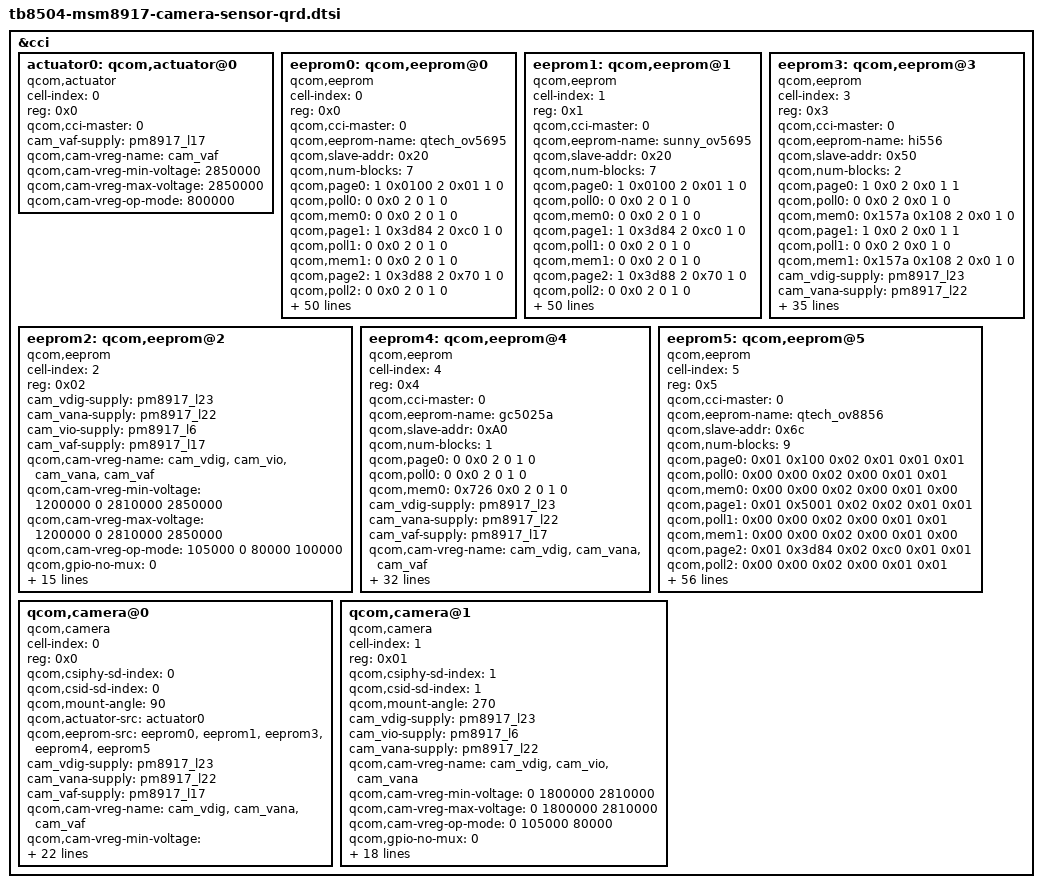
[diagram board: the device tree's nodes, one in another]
/*
 * Copyright (c) 2016, The Linux Foundation. All rights reserved.
 *
 * This program is free software; you can redistribute it and/or modify
 * it under the terms of the GNU General Public License version 2 and
 * only version 2 as published by the Free Software Foundation.
 *
 * This program is distributed in the hope that it will be useful,
 * but WITHOUT ANY WARRANTY; without even the implied warranty of
 * MERCHANTABILITY or FITNESS FOR A PARTICULAR PURPOSE.  See the
 * GNU General Public License for more details.
 */
&cci {
	actuator0: qcom,actuator@0 {
		cell-index = <0>;
		reg = <0x0>;
		compatible = "qcom,actuator";
		qcom,cci-master = <0>;
		cam_vaf-supply = <&pm8917_l17>;
		qcom,cam-vreg-name = "cam_vaf";
		qcom,cam-vreg-min-voltage = <2850000>;
		qcom,cam-vreg-max-voltage = <2850000>;
		qcom,cam-vreg-op-mode = <800000>;
	};

	eeprom0: qcom,eeprom@0 {
		cell-index = <0>;
		reg = <0x0>;
		compatible = "qcom,eeprom";
		qcom,cci-master = <0>;

		qcom,eeprom-name = "qtech_ov5695";
		qcom,slave-addr = <0x20>;
		qcom,num-blocks = <7>;
		qcom,page0 = <1 0x0100 2 0x01 1 0>;//Stream on mode
		qcom,poll0 = <0 0x0 2 0 1 0>;
		qcom,mem0 = <0 0x0 2 0 1 0>;
		qcom,page1 = <1 0x3d84 2 0xc0 1 0>;//manual made
		qcom,poll1 = <0 0x0 2 0 1 0>;
		qcom,mem1 = <0 0x0 2 0 1 0>;
		qcom,page2 = <1 0x3d88 2 0x70 1 0>;//star address high
		qcom,poll2 = <0 0x0 2 0 1 0>;
		qcom,mem2 = <0 0x0 2 0 1 0>;
		qcom,page3 = <1 0x3d89 2 0x0c 1 0>;//star address low
		qcom,poll3 = <0 0x0 2 0 1 0>;
		qcom,mem3 = <0 0x0 2 0 1 0>;
		qcom,page4 = <1 0x3d8a 2 0x70 1 0>;//end address high
		qcom,poll4 = <0 0x0 2 0 1 0>;
		qcom,mem4 = <0 0x0 2 0 1 0>;
		qcom,page5 = <1 0x3d8b 2 0x1b 1 0>;//end address low
		qcom,poll5 = <0 0x0 2 0 1 0>;
		qcom,mem5 = <0 0x0 2 0 1 0>;
		qcom,page6 = <1 0x3d81 2 0x01 1 5>;//Page Read Enable
		qcom,poll6 = <0 0x0 2 0 1 0>;
		qcom,mem6 = <16 0x700c 2 0 1 0>;//read 

		cam_vdig-supply = <&pm8917_l23>;
		cam_vana-supply = <&pm8917_l22>;
		cam_vaf-supply = <&pm8917_l17>;
		qcom,cam-vreg-name = "cam_vdig", "cam_vana", "cam_vaf";
		qcom,cam-vreg-min-voltage = <1200000 2810000 2850000>;
		qcom,cam-vreg-max-voltage = <1200000 2810000 2850000>;
		qcom,cam-vreg-op-mode = <100000 800000 800000>;
		pinctrl-names = "cam_default", "cam_suspend";
		pinctrl-0 = <&cam_sensor_mclk0_default
				&cam_sensor_rear_default>;
		pinctrl-1 = <&cam_sensor_mclk0_sleep
				&cam_sensor_rear_sleep>;
		gpios = <&tlmm 26 0>,
			<&tlmm 36 0>,
			<&tlmm 35 0>,
			<&tlmm 34 0>;
		qcom,gpio-reset = <1>;
		qcom,gpio-standby = <2>;
		qcom,gpio-vio = <3>;
		qcom,gpio-req-tbl-num = <0 1 2 3>;
		qcom,gpio-req-tbl-flags = <1 0 0 0>;
		qcom,gpio-req-tbl-label = "CAMIF_MCLK0",
					  "CAM_RESET0",
					  "CAM_STANDBY0",
					  "CAM_VIO0";

		qcom,cam-power-seq-type = "sensor_vreg",
					  "sensor_gpio",
					  "sensor_vreg",
					  "sensor_vreg",
					  "sensor_clk",
					  "sensor_gpio",
					  "sensor_gpio",
					  "sensor_gpio",
					  "sensor_gpio";
		qcom,cam-power-seq-val =  "cam_vaf",
					  "sensor_gpio_vio",
					  "cam_vana",
					  "cam_vdig",
					  "sensor_cam_mclk",
					  "sensor_gpio_standby",
					  "sensor_gpio_reset",
					  "sensor_gpio_standby",
					  "sensor_gpio_reset";
		qcom,cam-power-seq-cfg-val = <1 1 1 1 24000000 0 0 1 1>;
		qcom,cam-power-seq-delay = <5 0 0 0 1 1 1 1 1>;

		status = "ok";

		clocks = <&clock_gcc clk_mclk0_clk_src>,
				<&clock_gcc clk_gcc_camss_mclk0_clk>;
		clock-names = "cam_src_clk", "cam_clk";
		qcom,clock-rates = <19200000 0>;
		/delete-property/ cam_vio-supply;
	};
	eeprom1: qcom,eeprom@1 {
		cell-index = <1>;
		reg = <0x1>;
		compatible = "qcom,eeprom";
		qcom,cci-master = <0>;

		qcom,eeprom-name = "sunny_ov5695";
		qcom,slave-addr = <0x20>;
		qcom,num-blocks = <7>;
		qcom,page0 = <1 0x0100 2 0x01 1 0>;//Stream on mode
		qcom,poll0 = <0 0x0 2 0 1 0>;
		qcom,mem0 = <0 0x0 2 0 1 0>;
		qcom,page1 = <1 0x3d84 2 0xc0 1 0>;//manual made
		qcom,poll1 = <0 0x0 2 0 1 0>;
		qcom,mem1 = <0 0x0 2 0 1 0>;
		qcom,page2 = <1 0x3d88 2 0x70 1 0>;//star address high
		qcom,poll2 = <0 0x0 2 0 1 0>;
		qcom,mem2 = <0 0x0 2 0 1 0>;
		qcom,page3 = <1 0x3d89 2 0x0c 1 0>;//star address low
		qcom,poll3 = <0 0x0 2 0 1 0>;
		qcom,mem3 = <0 0x0 2 0 1 0>;
		qcom,page4 = <1 0x3d8a 2 0x70 1 0>;//end address high
		qcom,poll4 = <0 0x0 2 0 1 0>;
		qcom,mem4 = <0 0x0 2 0 1 0>;
		qcom,page5 = <1 0x3d8b 2 0x1b 1 0>;//end address low
		qcom,poll5 = <0 0x0 2 0 1 0>;
		qcom,mem5 = <0 0x0 2 0 1 0>;
		qcom,page6 = <1 0x3d81 2 0x01 1 5>;//Page Read Enable
		qcom,poll6 = <0 0x0 2 0 1 0>;
		qcom,mem6 = <16 0x700c 2 0 1 0>;//read 

		cam_vdig-supply = <&pm8917_l23>;
		cam_vana-supply = <&pm8917_l22>;
		cam_vaf-supply = <&pm8917_l17>;
		qcom,cam-vreg-name = "cam_vdig", "cam_vana", "cam_vaf";
		qcom,cam-vreg-min-voltage = <1200000 2810000 2850000>;
		qcom,cam-vreg-max-voltage = <1200000 2810000 2850000>;
		qcom,cam-vreg-op-mode = <100000 800000 800000>;
		pinctrl-names = "cam_default", "cam_suspend";
		pinctrl-0 = <&cam_sensor_mclk0_default
				&cam_sensor_rear_default>;
		pinctrl-1 = <&cam_sensor_mclk0_sleep
				&cam_sensor_rear_sleep>;
		gpios = <&tlmm 26 0>,
			<&tlmm 36 0>,
			<&tlmm 35 0>,
			<&tlmm 34 0>;
		qcom,gpio-reset = <1>;
		qcom,gpio-standby = <2>;
		qcom,gpio-vio = <3>;
		qcom,gpio-req-tbl-num = <0 1 2 3>;
		qcom,gpio-req-tbl-flags = <1 0 0 0>;
		qcom,gpio-req-tbl-label = "CAMIF_MCLK0",
					  "CAM_RESET0",
					  "CAM_STANDBY0",
					  "CAM_VIO0";

		qcom,cam-power-seq-type = "sensor_vreg",
					  "sensor_gpio",
					  "sensor_vreg",
					  "sensor_vreg",
					  "sensor_clk",
					  "sensor_gpio",
					  "sensor_gpio",
					  "sensor_gpio",
					  "sensor_gpio";
		qcom,cam-power-seq-val =  "cam_vaf",
					  "sensor_gpio_vio",
					  "cam_vana",
					  "cam_vdig",
					  "sensor_cam_mclk",
					  "sensor_gpio_standby",
					  "sensor_gpio_reset",
					  "sensor_gpio_standby",
					  "sensor_gpio_reset";
		qcom,cam-power-seq-cfg-val = <1 1 1 1 24000000 0 0 1 1>;
		qcom,cam-power-seq-delay = <5 0 0 0 1 1 1 1 1>;

		status = "ok";

		clocks = <&clock_gcc clk_mclk0_clk_src>,
				<&clock_gcc clk_gcc_camss_mclk0_clk>;
		clock-names = "cam_src_clk", "cam_clk";
		qcom,clock-rates = <19200000 0>;
	};
	eeprom2: qcom,eeprom@2 {
		cell-index = <2>;
		compatible = "qcom,eeprom";
		reg = <0x02>;
		cam_vdig-supply = <&pm8917_l23>;
		cam_vana-supply = <&pm8917_l22>;
		cam_vio-supply = <&pm8917_l6>;
		cam_vaf-supply = <&pm8917_l17>;
		qcom,cam-vreg-name = "cam_vdig", "cam_vio", "cam_vana",
								"cam_vaf";
		qcom,cam-vreg-min-voltage = <1200000 0 2810000 2850000>;
		qcom,cam-vreg-max-voltage = <1200000 0 2810000 2850000>;
		qcom,cam-vreg-op-mode = <105000 0 80000 100000>;
		qcom,gpio-no-mux = <0>;
		pinctrl-names = "cam_default", "cam_suspend";
		pinctrl-0 = <&cam_sensor_mclk2_default
					&cam_sensor_front1_default>;
		pinctrl-1 = <&cam_sensor_mclk2_sleep
					&cam_sensor_front1_sleep>;
		gpios = <&tlmm 28 0>,
			<&tlmm 40 0>,
			<&tlmm 39 0>;
		qcom,gpio-reset = <1>;
		qcom,gpio-standby = <2>;
		qcom,gpio-req-tbl-num = <0 1 2>;
		qcom,gpio-req-tbl-flags = <1 0 0>;
		qcom,gpio-req-tbl-label = "CAMIF_MCLK2",
					  "CAM_RESET2",
					  "CAM_STANDBY2";
		qcom,cci-master = <0>;
		status = "ok";
		clocks = <&clock_gcc clk_mclk2_clk_src>,
			<&clock_gcc clk_gcc_camss_mclk2_clk>;
		clock-names = "cam_src_clk", "cam_clk";
		qcom,clock-rates = <19200000 0>;
	};

// tom han add hi556_eeprom
eeprom3: qcom,eeprom@3 {
		cell-index = <3>;
		reg = <0x3>;
		compatible = "qcom,eeprom";
		qcom,cci-master = <0>;

		qcom,eeprom-name = "hi556";
		qcom,slave-addr = <0x50>;
		qcom,num-blocks = <2>;
		qcom,page0 = <1 0x0 2 0x0 1 1>;
		qcom,poll0 = <0 0x0 2 0x0 1 0>;
		qcom,mem0 = <0x157a 0x108 2 0x0 1 0>;
		qcom,page1 = <1 0x0 2 0x0 1 1>;
		qcom,poll1 = <0 0x0 2 0x0 1 0>;
		qcom,mem1= <0x157a 0x108 2 0x0 1 0>;

		cam_vdig-supply = <&pm8917_l23>;
		cam_vana-supply = <&pm8917_l22>;
		cam_vaf-supply = <&pm8917_l17>;
		qcom,cam-vreg-name = "cam_vdig", "cam_vana", "cam_vaf";
		qcom,cam-vreg-min-voltage = <1200000 2810000 2850000>;
		qcom,cam-vreg-max-voltage = <1200000 2810000 2850000>;
		qcom,cam-vreg-op-mode = <100000 800000 800000>;
		pinctrl-names = "cam_default", "cam_suspend";
		pinctrl-0 = <&cam_sensor_mclk0_default
				&cam_sensor_rear_default>;
		pinctrl-1 = <&cam_sensor_mclk0_sleep
				&cam_sensor_rear_sleep>;
		gpios = <&tlmm 26 0>,
			<&tlmm 36 0>,
			<&tlmm 35 0>,
			<&tlmm 34 0>;
		qcom,gpio-reset = <1>;
		qcom,gpio-standby = <2>;
		qcom,gpio-vio = <3>;
		qcom,gpio-req-tbl-num = <0 1 2 3>;
		qcom,gpio-req-tbl-flags = <1 0 0 0>;
		qcom,gpio-req-tbl-label = "CAMIF_MCLK0",
					  "CAM_RESET0",
					  "CAM_STANDBY0",
					  "CAM_VIO0";

		qcom,cam-power-seq-type = "sensor_vreg",
					  "sensor_gpio",
					  "sensor_vreg",
					  "sensor_vreg",
					  "sensor_clk",
					  "sensor_gpio",
					  "sensor_gpio",
					  "sensor_gpio",
					  "sensor_gpio";
		qcom,cam-power-seq-val =  "cam_vaf",
					  "sensor_gpio_vio",
					  "cam_vana",
					  "cam_vdig",
					  "sensor_cam_mclk",
					  "sensor_gpio_standby",
					  "sensor_gpio_reset",
					  "sensor_gpio_standby",
					  "sensor_gpio_reset";
		qcom,cam-power-seq-cfg-val = <1 1 1 1 24000000 0 0 1 1>;
		qcom,cam-power-seq-delay = <5 0 0 0 1 1 1 1 1>;

		status = "ok";

		clocks = <&clock_gcc clk_mclk0_clk_src>,
				<&clock_gcc clk_gcc_camss_mclk0_clk>;
		clock-names = "cam_src_clk", "cam_clk";
		qcom,clock-rates = <19200000 0>;
	};

// tom han add GC5025A_eeprom
eeprom4: qcom,eeprom@4 {
		cell-index = <4>;
		reg = <0x4>;
		compatible = "qcom,eeprom";
		qcom,cci-master = <0>;

		qcom,eeprom-name = "gc5025a";
		qcom,slave-addr = <0xA0>;
		qcom,num-blocks = <1>;
		
		qcom,page0 = <0 0x0 2 0 1 0>;
		qcom,poll0 = <0 0x0 2 0 1 0>;
		qcom,mem0 = <0x726 0x0 2 0 1 0>;//read 

		cam_vdig-supply = <&pm8917_l23>;
		cam_vana-supply = <&pm8917_l22>;
		cam_vaf-supply = <&pm8917_l17>;
		qcom,cam-vreg-name = "cam_vdig", "cam_vana", "cam_vaf";
		qcom,cam-vreg-min-voltage = <1200000 2810000 2850000>;
		qcom,cam-vreg-max-voltage = <1200000 2810000 2850000>;
		qcom,cam-vreg-op-mode = <100000 800000 800000>;
		pinctrl-names = "cam_default", "cam_suspend";
		pinctrl-0 = <&cam_sensor_mclk0_default
				&cam_sensor_rear_default>;
		pinctrl-1 = <&cam_sensor_mclk0_sleep
				&cam_sensor_rear_sleep>;
		gpios = <&tlmm 26 0>,
			<&tlmm 36 0>,
			<&tlmm 35 0>,
			<&tlmm 34 0>;
		qcom,gpio-reset = <1>;
		qcom,gpio-standby = <2>;
		qcom,gpio-vio = <3>;
		qcom,gpio-req-tbl-num = <0 1 2 3>;
		qcom,gpio-req-tbl-flags = <1 0 0 0>;
		qcom,gpio-req-tbl-label = "CAMIF_MCLK0",
					  "CAM_RESET0",
					  "CAM_STANDBY0",
					  "CAM_VIO0";

		qcom,cam-power-seq-type = "sensor_vreg",
					  "sensor_gpio",
					  "sensor_vreg",
					  "sensor_vreg",
					  "sensor_clk",
					  "sensor_gpio",
					  "sensor_gpio",
					  "sensor_gpio",
					  "sensor_gpio";
		qcom,cam-power-seq-val =  "cam_vaf",
					  "sensor_gpio_vio",
					  "cam_vana",
					  "cam_vdig",
					  "sensor_cam_mclk",
					  "sensor_gpio_standby",
					  "sensor_gpio_reset",
					  "sensor_gpio_standby",
					  "sensor_gpio_reset";
		qcom,cam-power-seq-cfg-val = <1 1 1 1 24000000 0 0 1 1>;
		qcom,cam-power-seq-delay = <5 0 0 0 1 1 1 1 1>;

		status = "ok";

		clocks = <&clock_gcc clk_mclk0_clk_src>,
				<&clock_gcc clk_gcc_camss_mclk0_clk>;
		clock-names = "cam_src_clk", "cam_clk";
		qcom,clock-rates = <19200000 0>;
	};

	eeprom5: qcom,eeprom@5 {
		cell-index = <5>;
		reg = <0x5>;
		compatible = "qcom,eeprom";
		qcom,cci-master = <0>;

		qcom,eeprom-name = "qtech_ov8856";
		qcom,slave-addr = <0x6c>;
		qcom,num-blocks = <9>;

		qcom,page0 = <0x01 0x100 0x02 0x01 0x01 0x01>;
		qcom,poll0 = <0x00 0x00 0x02 0x00 0x01 0x01>;
		qcom,mem0 = <0x00 0x00 0x02 0x00 0x01 0x00>;
		qcom,page1 = <0x01 0x5001 0x02 0x02 0x01 0x01>;
		qcom,poll1 = <0x00 0x00 0x02 0x00 0x01 0x01>;
		qcom,mem1 = <0x00 0x00 0x02 0x00 0x01 0x00>;
		qcom,page2 = <0x01 0x3d84 0x02 0xc0 0x01 0x01>;
		qcom,poll2 = <0x00 0x00 0x02 0x00 0x01 0x01>;
		qcom,mem2 = <0x00 0x00 0x02 0x00 0x01 0x00>;
		qcom,page3 = <0x01 0x3d88 0x02 0x70 0x01 0x01>;
		qcom,poll3 = <0x00 0x00 0x02 0x00 0x01 0x01>;
		qcom,mem3 = <0x00 0x00 0x02 0x00 0x01 0x00>;
		qcom,page4 = <0x01 0x3d89 0x02 0x10 0x01 0x01>;
		qcom,poll4 = <0x00 0x00 0x02 0x00 0x01 0x01>;
		qcom,mem4 = <0x00 0x00 0x02 0x00 0x01 0x00>;
		qcom,page5 = <0x01 0x3d8a 0x02 0x72 0x01 0x00>;
		qcom,poll5 = <0x00 0x00 0x02 0x00 0x01 0x01>;
		qcom,mem5 = <0x00 0x00 0x02 0x00 0x01 0x00>;
		qcom,page6 = <0x01 0x3d8b 0x02 0x0f 0x01 0x0a>;
		qcom,poll6 = <0x00 0x00 0x02 0x00 0x01 0x01>;
		qcom,mem6 = <0x00 0x00 0x02 0x00 0x01 0x00>;
		qcom,page7 = <0x01 0x3d81 0x02 0x01 0x01 0x0a>;
		qcom,poll7 = <0x00 0x00 0x02 0x00 0x01 0x01>;
		qcom,mem7 = <0x200 0x7010 0x02 0x00 0x01 0x05>;
		qcom,page8 = <0x01 0x5001 0x02 0x0a 0x01 0x05>;
		qcom,poll8 = <0x00 0x00 0x02 0x00 0x01 0x01>;
		qcom,mem8 = <0x01 0x5000 0x02 0x00 0x01 0x01>;


		cam_vdig-supply = <&pm8917_l23>;
		cam_vana-supply = <&pm8917_l22>;
		cam_vaf-supply = <&pm8917_l17>;
		qcom,cam-vreg-name = "cam_vdig", "cam_vana", "cam_vaf";
		qcom,cam-vreg-min-voltage = <1200000 2810000 2850000>;
		qcom,cam-vreg-max-voltage = <1200000 2810000 2850000>;
		qcom,cam-vreg-op-mode = <100000 800000 800000>;
		pinctrl-names = "cam_default", "cam_suspend";
		pinctrl-0 = <&cam_sensor_mclk0_default
				&cam_sensor_rear_default>;
		pinctrl-1 = <&cam_sensor_mclk0_sleep
				&cam_sensor_rear_sleep>;
		gpios = <&tlmm 26 0>,
			<&tlmm 36 0>,
			<&tlmm 35 0>,
			<&tlmm 34 0>;
		qcom,gpio-reset = <1>;
		qcom,gpio-standby = <2>;
		qcom,gpio-vio = <3>;
		qcom,gpio-req-tbl-num = <0 1 2 3>;
		qcom,gpio-req-tbl-flags = <1 0 0 0>;
		qcom,gpio-req-tbl-label = "CAMIF_MCLK0",
					  "CAM_RESET0",
					  "CAM_STANDBY0",
					  "CAM_VIO0";

		qcom,cam-power-seq-type = "sensor_vreg",
					  "sensor_gpio",
					  "sensor_vreg",
					  "sensor_vreg",
					  "sensor_clk",
					  "sensor_gpio",
					  "sensor_gpio",
					  "sensor_gpio",
					  "sensor_gpio";
		qcom,cam-power-seq-val =  "cam_vaf",
					  "sensor_gpio_vio",
					  "cam_vana",
					  "cam_vdig",
					  "sensor_cam_mclk",
					  "sensor_gpio_standby",
					  "sensor_gpio_reset",
					  "sensor_gpio_standby",
					  "sensor_gpio_reset";
		qcom,cam-power-seq-cfg-val = <1 1 1 1 24000000 0 0 1 1>;
		qcom,cam-power-seq-delay = <5 0 0 0 1 1 1 1 1>;

		status = "ok";

		clocks = <&clock_gcc clk_mclk0_clk_src>,
				<&clock_gcc clk_gcc_camss_mclk0_clk>;
		clock-names = "cam_src_clk", "cam_clk";
		qcom,clock-rates = <19200000 0>;
	};


	qcom,camera@0 {
		cell-index = <0>;
		compatible = "qcom,camera";
		reg = <0x0>;
		qcom,csiphy-sd-index = <0>;
		qcom,csid-sd-index = <0>;
		qcom,mount-angle = <90>;
		qcom,actuator-src = <&actuator0>;
		//qcom,led-flash-src = <&led_flash0>;
		qcom,eeprom-src = <&eeprom0 &eeprom1 &eeprom3 &eeprom4 &eeprom5>;
		cam_vdig-supply = <&pm8917_l23>;
		cam_vana-supply = <&pm8917_l22>;
		cam_vaf-supply = <&pm8917_l17>;
		qcom,cam-vreg-name = "cam_vdig", "cam_vana", "cam_vaf";
		//qcom,cam-vreg-name = "cam_vdig", "cam_vio", "cam_vana", "cam_vaf";
		qcom,cam-vreg-min-voltage = <1200000 2810000 2850000>;
		qcom,cam-vreg-max-voltage = <1200000 2810000 2850000>;
		qcom,cam-vreg-op-mode = <100000 800000 800000>;
		pinctrl-names = "cam_default", "cam_suspend";
		pinctrl-0 = <&cam_sensor_mclk0_default
				&cam_sensor_rear_default>;
		pinctrl-1 = <&cam_sensor_mclk0_sleep
				&cam_sensor_rear_sleep>;
		gpios = <&tlmm 26 0>,
			<&tlmm 36 0>,
			<&tlmm 35 0>,
			<&tlmm 34 0>;
		qcom,gpio-reset = <1>;
		qcom,gpio-standby = <2>;
		qcom,gpio-vio = <3>;
		qcom,gpio-req-tbl-num = <0 1 2 3>;
		qcom,gpio-req-tbl-flags = <1 0 0 0>;
		qcom,gpio-req-tbl-label = "CAMIF_MCLK0",
			"CAM_RESET0",
			"CAM_STANDBY0",
			"CAM_VIO0";
		qcom,sensor-position = <0>;
		qcom,sensor-mode = <0>;
		qcom,cci-master = <0>;
		clocks = <&clock_gcc clk_mclk0_clk_src>,
			<&clock_gcc clk_gcc_camss_mclk0_clk>;
		clock-names = "cam_src_clk", "cam_clk";
		qcom,clock-rates = <24000000 0>;
		/delete-property/ qcom,led-flash-src;
		/delete-property/ cam_vio-supply;
	};

	qcom,camera@1 {//sp2509
		cell-index = <1>;
		compatible = "qcom,camera";
		reg = <0x01>;
		qcom,csiphy-sd-index = <1>;
		qcom,csid-sd-index = <1>;
		qcom,mount-angle = <270>;
		cam_vdig-supply = <&pm8917_l23>;
		cam_vio-supply = <&pm8917_l6>;
                cam_vana-supply = <&pm8917_l22>;
		qcom,cam-vreg-name = "cam_vdig", "cam_vio", "cam_vana";
		qcom,cam-vreg-min-voltage = <0 1800000 2810000>;
		qcom,cam-vreg-max-voltage = <0 1800000 2810000>;
		qcom,cam-vreg-op-mode = <0 105000 80000>;
		qcom,gpio-no-mux = <0>;
		pinctrl-names = "cam_default", "cam_suspend";
		pinctrl-0 = <&cam_sensor_mclk1_default
				&cam_sensor_front1_default>;
		pinctrl-1 = <&cam_sensor_mclk1_sleep
				&cam_sensor_front1_sleep>;
		gpios = <&tlmm 27 0>,
			<&tlmm 40 0>,
			<&tlmm 39 0>,
			<&tlmm 34 0>;
		qcom,gpio-reset = <1>;
		qcom,gpio-standby = <2>;
		qcom,gpio-vio = <3>;
		qcom,gpio-req-tbl-num = <0 1 2 3>;
		qcom,gpio-req-tbl-flags = <1 0 0 0>;
		qcom,gpio-req-tbl-label = "CAMIF_MCLK1",
					  "CAM_RESET1",
					  "CAM_STANDBY1",
					  "CAM_VIO0";
		qcom,sensor-position = <1>;
		qcom,sensor-mode = <0>;
		qcom,cci-master = <0>;
		clocks = <&clock_gcc clk_mclk1_clk_src>,
			<&clock_gcc clk_gcc_camss_mclk1_clk>;
		clock-names = "cam_src_clk", "cam_clk";
		qcom,clock-rates = <24000000 0>;
	};
	
	/delete-node/ qcom,camera@2;
};
